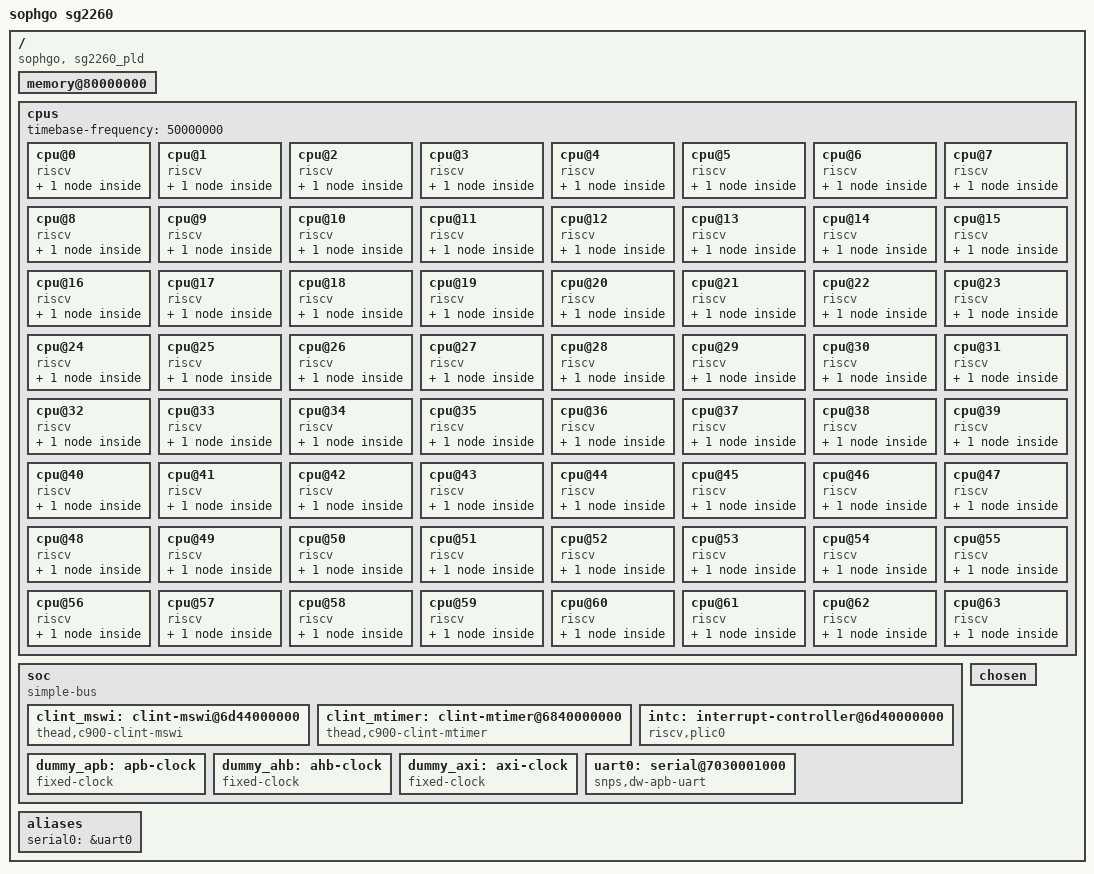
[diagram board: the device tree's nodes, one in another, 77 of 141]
/dts-v1/;
/ {
	model = "sophgo sg2260";
	compatible = "sophgo, sg2260_pld";
	#address-cells = <2>;
	#size-cells = <2>;
	dma-noncoherent;

	memory@80000000 {
		device_type = "memory";
		reg = <0x00000000 0x80000000 0x00000000 0x80000000>;
	};

	cpus {
		#address-cells = <1>;
		#size-cells = <0>;
		timebase-frequency = <50000000>;
		cpu@0 {
			device_type = "cpu";
			reg = <0>;
			status = "okay";
			compatible = "riscv";
			riscv,isa = "rv64imafdcv_zicbom_zicbop_zicboz_zicond1p0_zihintntl0p2_zihintpause_zawrs_zfa0p1_zfbfmin0p8_zfh_zca_zcb_zcd_zba_zbb_zbc_zbs_zvfbfmin0p8_zvfbfwma0p8_zvfh0p1_sscofpmf_sstc_svinval_svnapot_svpbmt_xtheadc_xtheadvdot";
			riscv,cbom-block-size = <64>;
			riscv,cboz-block-size = <64>;
			mmu-type = "riscv,sv48";
			cpu0_intc: interrupt-controller {
				#interrupt-cells = <1>;
				compatible = "riscv,cpu-intc";
				interrupt-controller;
			};
		};
		cpu@1 {
			device_type = "cpu";
			reg = <1>;
			status = "okay";
			compatible = "riscv";
			riscv,isa = "rv64imafdcv_zicbom_zicbop_zicboz_zicond1p0_zihintntl0p2_zihintpause_zawrs_zfa0p1_zfbfmin0p8_zfh_zca_zcb_zcd_zba_zbb_zbc_zbs_zvfbfmin0p8_zvfbfwma0p8_zvfh0p1_sscofpmf_sstc_svinval_svnapot_svpbmt_xtheadc_xtheadvdot";
			riscv,cbom-block-size = <64>;
			riscv,cboz-block-size = <64>;
			mmu-type = "riscv,sv48";
			cpu1_intc: interrupt-controller {
				#interrupt-cells = <1>;
				compatible = "riscv,cpu-intc";
				interrupt-controller;
			};
		};
		cpu@2 {
			device_type = "cpu";
			reg = <2>;
			status = "okay";
			compatible = "riscv";
			riscv,isa = "rv64imafdcv_zicbom_zicbop_zicboz_zicond1p0_zihintntl0p2_zihintpause_zawrs_zfa0p1_zfbfmin0p8_zfh_zca_zcb_zcd_zba_zbb_zbc_zbs_zvfbfmin0p8_zvfbfwma0p8_zvfh0p1_sscofpmf_sstc_svinval_svnapot_svpbmt_xtheadc_xtheadvdot";
			riscv,cbom-block-size = <64>;
			riscv,cboz-block-size = <64>;
			mmu-type = "riscv,sv48";
			cpu2_intc: interrupt-controller {
				#interrupt-cells = <1>;
				compatible = "riscv,cpu-intc";
				interrupt-controller;
			};
		};
		cpu@3 {
			device_type = "cpu";
			reg = <3>;
			status = "okay";
			compatible = "riscv";
			riscv,isa = "rv64imafdcv_zicbom_zicbop_zicboz_zicond1p0_zihintntl0p2_zihintpause_zawrs_zfa0p1_zfbfmin0p8_zfh_zca_zcb_zcd_zba_zbb_zbc_zbs_zvfbfmin0p8_zvfbfwma0p8_zvfh0p1_sscofpmf_sstc_svinval_svnapot_svpbmt_xtheadc_xtheadvdot";
			riscv,cbom-block-size = <64>;
			riscv,cboz-block-size = <64>;
			mmu-type = "riscv,sv48";
			cpu3_intc: interrupt-controller {
				#interrupt-cells = <1>;
				compatible = "riscv,cpu-intc";
				interrupt-controller;
			};
		};
		cpu@4 {
			device_type = "cpu";
			reg = <4>;
			status = "okay";
			compatible = "riscv";
			riscv,isa = "rv64imafdcv_zicbom_zicbop_zicboz_zicond1p0_zihintntl0p2_zihintpause_zawrs_zfa0p1_zfbfmin0p8_zfh_zca_zcb_zcd_zba_zbb_zbc_zbs_zvfbfmin0p8_zvfbfwma0p8_zvfh0p1_sscofpmf_sstc_svinval_svnapot_svpbmt_xtheadc_xtheadvdot";
			riscv,cbom-block-size = <64>;
			riscv,cboz-block-size = <64>;
			mmu-type = "riscv,sv48";
			cpu4_intc: interrupt-controller {
				#interrupt-cells = <1>;
				compatible = "riscv,cpu-intc";
				interrupt-controller;
			};
		};
		cpu@5 {
			device_type = "cpu";
			reg = <5>;
			status = "okay";
			compatible = "riscv";
			riscv,isa = "rv64imafdcv_zicbom_zicbop_zicboz_zicond1p0_zihintntl0p2_zihintpause_zawrs_zfa0p1_zfbfmin0p8_zfh_zca_zcb_zcd_zba_zbb_zbc_zbs_zvfbfmin0p8_zvfbfwma0p8_zvfh0p1_sscofpmf_sstc_svinval_svnapot_svpbmt_xtheadc_xtheadvdot";
			riscv,cbom-block-size = <64>;
			riscv,cboz-block-size = <64>;
			mmu-type = "riscv,sv48";
			cpu5_intc: interrupt-controller {
				#interrupt-cells = <1>;
				compatible = "riscv,cpu-intc";
				interrupt-controller;
			};
		};
		cpu@6 {
			device_type = "cpu";
			reg = <6>;
			status = "okay";
			compatible = "riscv";
			riscv,isa = "rv64imafdcv_zicbom_zicbop_zicboz_zicond1p0_zihintntl0p2_zihintpause_zawrs_zfa0p1_zfbfmin0p8_zfh_zca_zcb_zcd_zba_zbb_zbc_zbs_zvfbfmin0p8_zvfbfwma0p8_zvfh0p1_sscofpmf_sstc_svinval_svnapot_svpbmt_xtheadc_xtheadvdot";
			riscv,cbom-block-size = <64>;
			riscv,cboz-block-size = <64>;
			mmu-type = "riscv,sv48";
			cpu6_intc: interrupt-controller {
				#interrupt-cells = <1>;
				compatible = "riscv,cpu-intc";
				interrupt-controller;
			};
		};
		cpu@7 {
			device_type = "cpu";
			reg = <7>;
			status = "okay";
			compatible = "riscv";
			riscv,isa = "rv64imafdcv_zicbom_zicbop_zicboz_zicond1p0_zihintntl0p2_zihintpause_zawrs_zfa0p1_zfbfmin0p8_zfh_zca_zcb_zcd_zba_zbb_zbc_zbs_zvfbfmin0p8_zvfbfwma0p8_zvfh0p1_sscofpmf_sstc_svinval_svnapot_svpbmt_xtheadc_xtheadvdot";
			riscv,cbom-block-size = <64>;
			riscv,cboz-block-size = <64>;
			mmu-type = "riscv,sv48";
			cpu7_intc: interrupt-controller {
				#interrupt-cells = <1>;
				compatible = "riscv,cpu-intc";
				interrupt-controller;
			};
		};
		cpu@8 {
			device_type = "cpu";
			reg = <8>;
			status = "okay";
			compatible = "riscv";
			riscv,isa = "rv64imafdcv_zicbom_zicbop_zicboz_zicond1p0_zihintntl0p2_zihintpause_zawrs_zfa0p1_zfbfmin0p8_zfh_zca_zcb_zcd_zba_zbb_zbc_zbs_zvfbfmin0p8_zvfbfwma0p8_zvfh0p1_sscofpmf_sstc_svinval_svnapot_svpbmt_xtheadc_xtheadvdot";
			riscv,cbom-block-size = <64>;
			riscv,cboz-block-size = <64>;
			mmu-type = "riscv,sv48";
			cpu8_intc: interrupt-controller {
				#interrupt-cells = <1>;
				compatible = "riscv,cpu-intc";
				interrupt-controller;
			};
		};
		cpu@9 {
			device_type = "cpu";
			reg = <9>;
			status = "okay";
			compatible = "riscv";
			riscv,isa = "rv64imafdcv_zicbom_zicbop_zicboz_zicond1p0_zihintntl0p2_zihintpause_zawrs_zfa0p1_zfbfmin0p8_zfh_zca_zcb_zcd_zba_zbb_zbc_zbs_zvfbfmin0p8_zvfbfwma0p8_zvfh0p1_sscofpmf_sstc_svinval_svnapot_svpbmt_xtheadc_xtheadvdot";
			riscv,cbom-block-size = <64>;
			riscv,cboz-block-size = <64>;
			mmu-type = "riscv,sv48";
			cpu9_intc: interrupt-controller {
				#interrupt-cells = <1>;
				compatible = "riscv,cpu-intc";
				interrupt-controller;
			};
		};
		cpu@10 {
			device_type = "cpu";
			reg = <10>;
			status = "okay";
			compatible = "riscv";
			riscv,isa = "rv64imafdcv_zicbom_zicbop_zicboz_zicond1p0_zihintntl0p2_zihintpause_zawrs_zfa0p1_zfbfmin0p8_zfh_zca_zcb_zcd_zba_zbb_zbc_zbs_zvfbfmin0p8_zvfbfwma0p8_zvfh0p1_sscofpmf_sstc_svinval_svnapot_svpbmt_xtheadc_xtheadvdot";
			riscv,cbom-block-size = <64>;
			riscv,cboz-block-size = <64>;
			mmu-type = "riscv,sv48";
			cpu10_intc: interrupt-controller {
				#interrupt-cells = <1>;
				compatible = "riscv,cpu-intc";
				interrupt-controller;
			};
		};
		cpu@11 {
			device_type = "cpu";
			reg = <11>;
			status = "okay";
			compatible = "riscv";
			riscv,isa = "rv64imafdcv_zicbom_zicbop_zicboz_zicond1p0_zihintntl0p2_zihintpause_zawrs_zfa0p1_zfbfmin0p8_zfh_zca_zcb_zcd_zba_zbb_zbc_zbs_zvfbfmin0p8_zvfbfwma0p8_zvfh0p1_sscofpmf_sstc_svinval_svnapot_svpbmt_xtheadc_xtheadvdot";
			riscv,cbom-block-size = <64>;
			riscv,cboz-block-size = <64>;
			mmu-type = "riscv,sv48";
			cpu11_intc: interrupt-controller {
				#interrupt-cells = <1>;
				compatible = "riscv,cpu-intc";
				interrupt-controller;
			};
		};
		cpu@12 {
			device_type = "cpu";
			reg = <12>;
			status = "okay";
			compatible = "riscv";
			riscv,isa = "rv64imafdcv_zicbom_zicbop_zicboz_zicond1p0_zihintntl0p2_zihintpause_zawrs_zfa0p1_zfbfmin0p8_zfh_zca_zcb_zcd_zba_zbb_zbc_zbs_zvfbfmin0p8_zvfbfwma0p8_zvfh0p1_sscofpmf_sstc_svinval_svnapot_svpbmt_xtheadc_xtheadvdot";
			riscv,cbom-block-size = <64>;
			riscv,cboz-block-size = <64>;
			mmu-type = "riscv,sv48";
			cpu12_intc: interrupt-controller {
				#interrupt-cells = <1>;
				compatible = "riscv,cpu-intc";
				interrupt-controller;
			};
		};
		cpu@13 {
			device_type = "cpu";
			reg = <13>;
			status = "okay";
			compatible = "riscv";
			riscv,isa = "rv64imafdcv_zicbom_zicbop_zicboz_zicond1p0_zihintntl0p2_zihintpause_zawrs_zfa0p1_zfbfmin0p8_zfh_zca_zcb_zcd_zba_zbb_zbc_zbs_zvfbfmin0p8_zvfbfwma0p8_zvfh0p1_sscofpmf_sstc_svinval_svnapot_svpbmt_xtheadc_xtheadvdot";
			riscv,cbom-block-size = <64>;
			riscv,cboz-block-size = <64>;
			mmu-type = "riscv,sv48";
			cpu13_intc: interrupt-controller {
				#interrupt-cells = <1>;
				compatible = "riscv,cpu-intc";
				interrupt-controller;
			};
		};
		cpu@14 {
			device_type = "cpu";
			reg = <14>;
			status = "okay";
			compatible = "riscv";
			riscv,isa = "rv64imafdcv_zicbom_zicbop_zicboz_zicond1p0_zihintntl0p2_zihintpause_zawrs_zfa0p1_zfbfmin0p8_zfh_zca_zcb_zcd_zba_zbb_zbc_zbs_zvfbfmin0p8_zvfbfwma0p8_zvfh0p1_sscofpmf_sstc_svinval_svnapot_svpbmt_xtheadc_xtheadvdot";
			riscv,cbom-block-size = <64>;
			riscv,cboz-block-size = <64>;
			mmu-type = "riscv,sv48";
			cpu14_intc: interrupt-controller {
				#interrupt-cells = <1>;
				compatible = "riscv,cpu-intc";
				interrupt-controller;
			};
		};
		cpu@15 {
			device_type = "cpu";
			reg = <15>;
			status = "okay";
			compatible = "riscv";
			riscv,isa = "rv64imafdcv_zicbom_zicbop_zicboz_zicond1p0_zihintntl0p2_zihintpause_zawrs_zfa0p1_zfbfmin0p8_zfh_zca_zcb_zcd_zba_zbb_zbc_zbs_zvfbfmin0p8_zvfbfwma0p8_zvfh0p1_sscofpmf_sstc_svinval_svnapot_svpbmt_xtheadc_xtheadvdot";
			riscv,cbom-block-size = <64>;
			riscv,cboz-block-size = <64>;
			mmu-type = "riscv,sv48";
			cpu15_intc: interrupt-controller {
				#interrupt-cells = <1>;
				compatible = "riscv,cpu-intc";
				interrupt-controller;
			};
		};
		cpu@16 {
			device_type = "cpu";
			reg = <16>;
			status = "okay";
			compatible = "riscv";
			riscv,isa = "rv64imafdcv_zicbom_zicbop_zicboz_zicond1p0_zihintntl0p2_zihintpause_zawrs_zfa0p1_zfbfmin0p8_zfh_zca_zcb_zcd_zba_zbb_zbc_zbs_zvfbfmin0p8_zvfbfwma0p8_zvfh0p1_sscofpmf_sstc_svinval_svnapot_svpbmt_xtheadc_xtheadvdot";
			riscv,cbom-block-size = <64>;
			riscv,cboz-block-size = <64>;
			mmu-type = "riscv,sv48";
			cpu16_intc: interrupt-controller {
				#interrupt-cells = <1>;
				compatible = "riscv,cpu-intc";
				interrupt-controller;
			};
		};
		cpu@17 {
			device_type = "cpu";
			reg = <17>;
			status = "okay";
			compatible = "riscv";
			riscv,isa = "rv64imafdcv_zicbom_zicbop_zicboz_zicond1p0_zihintntl0p2_zihintpause_zawrs_zfa0p1_zfbfmin0p8_zfh_zca_zcb_zcd_zba_zbb_zbc_zbs_zvfbfmin0p8_zvfbfwma0p8_zvfh0p1_sscofpmf_sstc_svinval_svnapot_svpbmt_xtheadc_xtheadvdot";
			riscv,cbom-block-size = <64>;
			riscv,cboz-block-size = <64>;
			mmu-type = "riscv,sv48";
			cpu17_intc: interrupt-controller {
				#interrupt-cells = <1>;
				compatible = "riscv,cpu-intc";
				interrupt-controller;
			};
		};
		cpu@18 {
			device_type = "cpu";
			reg = <18>;
			status = "okay";
			compatible = "riscv";
			riscv,isa = "rv64imafdcv_zicbom_zicbop_zicboz_zicond1p0_zihintntl0p2_zihintpause_zawrs_zfa0p1_zfbfmin0p8_zfh_zca_zcb_zcd_zba_zbb_zbc_zbs_zvfbfmin0p8_zvfbfwma0p8_zvfh0p1_sscofpmf_sstc_svinval_svnapot_svpbmt_xtheadc_xtheadvdot";
			riscv,cbom-block-size = <64>;
			riscv,cboz-block-size = <64>;
			mmu-type = "riscv,sv48";
			cpu18_intc: interrupt-controller {
				#interrupt-cells = <1>;
				compatible = "riscv,cpu-intc";
				interrupt-controller;
			};
		};
		cpu@19 {
			device_type = "cpu";
			reg = <19>;
			status = "okay";
			compatible = "riscv";
			riscv,isa = "rv64imafdcv_zicbom_zicbop_zicboz_zicond1p0_zihintntl0p2_zihintpause_zawrs_zfa0p1_zfbfmin0p8_zfh_zca_zcb_zcd_zba_zbb_zbc_zbs_zvfbfmin0p8_zvfbfwma0p8_zvfh0p1_sscofpmf_sstc_svinval_svnapot_svpbmt_xtheadc_xtheadvdot";
			riscv,cbom-block-size = <64>;
			riscv,cboz-block-size = <64>;
			mmu-type = "riscv,sv48";
			cpu19_intc: interrupt-controller {
				#interrupt-cells = <1>;
				compatible = "riscv,cpu-intc";
				interrupt-controller;
			};
		};
		cpu@20 {
			device_type = "cpu";
			reg = <20>;
			status = "okay";
			compatible = "riscv";
			riscv,isa = "rv64imafdcv_zicbom_zicbop_zicboz_zicond1p0_zihintntl0p2_zihintpause_zawrs_zfa0p1_zfbfmin0p8_zfh_zca_zcb_zcd_zba_zbb_zbc_zbs_zvfbfmin0p8_zvfbfwma0p8_zvfh0p1_sscofpmf_sstc_svinval_svnapot_svpbmt_xtheadc_xtheadvdot";
			riscv,cbom-block-size = <64>;
			riscv,cboz-block-size = <64>;
			mmu-type = "riscv,sv48";
			cpu20_intc: interrupt-controller {
				#interrupt-cells = <1>;
				compatible = "riscv,cpu-intc";
				interrupt-controller;
			};
		};
		cpu@21 {
			device_type = "cpu";
			reg = <21>;
			status = "okay";
			compatible = "riscv";
			riscv,isa = "rv64imafdcv_zicbom_zicbop_zicboz_zicond1p0_zihintntl0p2_zihintpause_zawrs_zfa0p1_zfbfmin0p8_zfh_zca_zcb_zcd_zba_zbb_zbc_zbs_zvfbfmin0p8_zvfbfwma0p8_zvfh0p1_sscofpmf_sstc_svinval_svnapot_svpbmt_xtheadc_xtheadvdot";
			riscv,cbom-block-size = <64>;
			riscv,cboz-block-size = <64>;
			mmu-type = "riscv,sv48";
			cpu21_intc: interrupt-controller {
				#interrupt-cells = <1>;
				compatible = "riscv,cpu-intc";
				interrupt-controller;
			};
		};
		cpu@22 {
			device_type = "cpu";
			reg = <22>;
			status = "okay";
			compatible = "riscv";
			riscv,isa = "rv64imafdcv_zicbom_zicbop_zicboz_zicond1p0_zihintntl0p2_zihintpause_zawrs_zfa0p1_zfbfmin0p8_zfh_zca_zcb_zcd_zba_zbb_zbc_zbs_zvfbfmin0p8_zvfbfwma0p8_zvfh0p1_sscofpmf_sstc_svinval_svnapot_svpbmt_xtheadc_xtheadvdot";
			riscv,cbom-block-size = <64>;
			riscv,cboz-block-size = <64>;
			mmu-type = "riscv,sv48";
			cpu22_intc: interrupt-controller {
				#interrupt-cells = <1>;
				compatible = "riscv,cpu-intc";
				interrupt-controller;
			};
		};
		cpu@23 {
			device_type = "cpu";
			reg = <23>;
			status = "okay";
			compatible = "riscv";
			riscv,isa = "rv64imafdcv_zicbom_zicbop_zicboz_zicond1p0_zihintntl0p2_zihintpause_zawrs_zfa0p1_zfbfmin0p8_zfh_zca_zcb_zcd_zba_zbb_zbc_zbs_zvfbfmin0p8_zvfbfwma0p8_zvfh0p1_sscofpmf_sstc_svinval_svnapot_svpbmt_xtheadc_xtheadvdot";
			riscv,cbom-block-size = <64>;
			riscv,cboz-block-size = <64>;
			mmu-type = "riscv,sv48";
			cpu23_intc: interrupt-controller {
				#interrupt-cells = <1>;
				compatible = "riscv,cpu-intc";
				interrupt-controller;
			};
		};
		cpu@24 {
			device_type = "cpu";
			reg = <24>;
			status = "okay";
			compatible = "riscv";
			riscv,isa = "rv64imafdcv_zicbom_zicbop_zicboz_zicond1p0_zihintntl0p2_zihintpause_zawrs_zfa0p1_zfbfmin0p8_zfh_zca_zcb_zcd_zba_zbb_zbc_zbs_zvfbfmin0p8_zvfbfwma0p8_zvfh0p1_sscofpmf_sstc_svinval_svnapot_svpbmt_xtheadc_xtheadvdot";
			riscv,cbom-block-size = <64>;
			riscv,cboz-block-size = <64>;
			mmu-type = "riscv,sv48";
			cpu24_intc: interrupt-controller {
				#interrupt-cells = <1>;
				compatible = "riscv,cpu-intc";
				interrupt-controller;
			};
		};
		cpu@25 {
			device_type = "cpu";
			reg = <25>;
			status = "okay";
			compatible = "riscv";
			riscv,isa = "rv64imafdcv_zicbom_zicbop_zicboz_zicond1p0_zihintntl0p2_zihintpause_zawrs_zfa0p1_zfbfmin0p8_zfh_zca_zcb_zcd_zba_zbb_zbc_zbs_zvfbfmin0p8_zvfbfwma0p8_zvfh0p1_sscofpmf_sstc_svinval_svnapot_svpbmt_xtheadc_xtheadvdot";
			riscv,cbom-block-size = <64>;
			riscv,cboz-block-size = <64>;
			mmu-type = "riscv,sv48";
			cpu25_intc: interrupt-controller {
				#interrupt-cells = <1>;
				compatible = "riscv,cpu-intc";
				interrupt-controller;
			};
		};
		cpu@26 {
			device_type = "cpu";
			reg = <26>;
			status = "okay";
			compatible = "riscv";
			riscv,isa = "rv64imafdcv_zicbom_zicbop_zicboz_zicond1p0_zihintntl0p2_zihintpause_zawrs_zfa0p1_zfbfmin0p8_zfh_zca_zcb_zcd_zba_zbb_zbc_zbs_zvfbfmin0p8_zvfbfwma0p8_zvfh0p1_sscofpmf_sstc_svinval_svnapot_svpbmt_xtheadc_xtheadvdot";
			riscv,cbom-block-size = <64>;
			riscv,cboz-block-size = <64>;
			mmu-type = "riscv,sv48";
			cpu26_intc: interrupt-controller {
				#interrupt-cells = <1>;
				compatible = "riscv,cpu-intc";
				interrupt-controller;
			};
		};
		cpu@27 {
			device_type = "cpu";
			reg = <27>;
			status = "okay";
			compatible = "riscv";
			riscv,isa = "rv64imafdcv_zicbom_zicbop_zicboz_zicond1p0_zihintntl0p2_zihintpause_zawrs_zfa0p1_zfbfmin0p8_zfh_zca_zcb_zcd_zba_zbb_zbc_zbs_zvfbfmin0p8_zvfbfwma0p8_zvfh0p1_sscofpmf_sstc_svinval_svnapot_svpbmt_xtheadc_xtheadvdot";
			riscv,cbom-block-size = <64>;
			riscv,cboz-block-size = <64>;
			mmu-type = "riscv,sv48";
			cpu27_intc: interrupt-controller {
				#interrupt-cells = <1>;
				compatible = "riscv,cpu-intc";
				interrupt-controller;
			};
		};
		cpu@28 {
			device_type = "cpu";
			reg = <28>;
			status = "okay";
			compatible = "riscv";
			riscv,isa = "rv64imafdcv_zicbom_zicbop_zicboz_zicond1p0_zihintntl0p2_zihintpause_zawrs_zfa0p1_zfbfmin0p8_zfh_zca_zcb_zcd_zba_zbb_zbc_zbs_zvfbfmin0p8_zvfbfwma0p8_zvfh0p1_sscofpmf_sstc_svinval_svnapot_svpbmt_xtheadc_xtheadvdot";
			riscv,cbom-block-size = <64>;
			riscv,cboz-block-size = <64>;
			mmu-type = "riscv,sv48";
			cpu28_intc: interrupt-controller {
				#interrupt-cells = <1>;
				compatible = "riscv,cpu-intc";
				interrupt-controller;
			};
		};
		cpu@29 {
			device_type = "cpu";
			reg = <29>;
			status = "okay";
			compatible = "riscv";
			riscv,isa = "rv64imafdcv_zicbom_zicbop_zicboz_zicond1p0_zihintntl0p2_zihintpause_zawrs_zfa0p1_zfbfmin0p8_zfh_zca_zcb_zcd_zba_zbb_zbc_zbs_zvfbfmin0p8_zvfbfwma0p8_zvfh0p1_sscofpmf_sstc_svinval_svnapot_svpbmt_xtheadc_xtheadvdot";
			riscv,cbom-block-size = <64>;
			riscv,cboz-block-size = <64>;
			mmu-type = "riscv,sv48";
			cpu29_intc: interrupt-controller {
				#interrupt-cells = <1>;
				compatible = "riscv,cpu-intc";
				interrupt-controller;
			};
		};
		cpu@30 {
			device_type = "cpu";
			reg = <30>;
			status = "okay";
			compatible = "riscv";
			riscv,isa = "rv64imafdcv_zicbom_zicbop_zicboz_zicond1p0_zihintntl0p2_zihintpause_zawrs_zfa0p1_zfbfmin0p8_zfh_zca_zcb_zcd_zba_zbb_zbc_zbs_zvfbfmin0p8_zvfbfwma0p8_zvfh0p1_sscofpmf_sstc_svinval_svnapot_svpbmt_xtheadc_xtheadvdot";
			riscv,cbom-block-size = <64>;
			riscv,cboz-block-size = <64>;
			mmu-type = "riscv,sv48";
			cpu30_intc: interrupt-controller {
				#interrupt-cells = <1>;
				compatible = "riscv,cpu-intc";
				interrupt-controller;
			};
		};
		cpu@31 {
			device_type = "cpu";
			reg = <31>;
			status = "okay";
			compatible = "riscv";
			riscv,isa = "rv64imafdcv_zicbom_zicbop_zicboz_zicond1p0_zihintntl0p2_zihintpause_zawrs_zfa0p1_zfbfmin0p8_zfh_zca_zcb_zcd_zba_zbb_zbc_zbs_zvfbfmin0p8_zvfbfwma0p8_zvfh0p1_sscofpmf_sstc_svinval_svnapot_svpbmt_xtheadc_xtheadvdot";
			riscv,cbom-block-size = <64>;
			riscv,cboz-block-size = <64>;
			mmu-type = "riscv,sv48";
			cpu31_intc: interrupt-controller {
				#interrupt-cells = <1>;
				compatible = "riscv,cpu-intc";
				interrupt-controller;
			};
		};
		cpu@32 {
			device_type = "cpu";
			reg = <32>;
			status = "okay";
			compatible = "riscv";
			riscv,isa = "rv64imafdcv_zicbom_zicbop_zicboz_zicond1p0_zihintntl0p2_zihintpause_zawrs_zfa0p1_zfbfmin0p8_zfh_zca_zcb_zcd_zba_zbb_zbc_zbs_zvfbfmin0p8_zvfbfwma0p8_zvfh0p1_sscofpmf_sstc_svinval_svnapot_svpbmt_xtheadc_xtheadvdot";
			riscv,cbom-block-size = <64>;
			riscv,cboz-block-size = <64>;
			mmu-type = "riscv,sv48";
			cpu32_intc: interrupt-controller {
				#interrupt-cells = <1>;
				compatible = "riscv,cpu-intc";
				interrupt-controller;
			};
		};
		cpu@33 {
			device_type = "cpu";
			reg = <33>;
			status = "okay";
			compatible = "riscv";
			riscv,isa = "rv64imafdcv_zicbom_zicbop_zicboz_zicond1p0_zihintntl0p2_zihintpause_zawrs_zfa0p1_zfbfmin0p8_zfh_zca_zcb_zcd_zba_zbb_zbc_zbs_zvfbfmin0p8_zvfbfwma0p8_zvfh0p1_sscofpmf_sstc_svinval_svnapot_svpbmt_xtheadc_xtheadvdot";
			riscv,cbom-block-size = <64>;
			riscv,cboz-block-size = <64>;
			mmu-type = "riscv,sv48";
			cpu33_intc: interrupt-controller {
				#interrupt-cells = <1>;
				compatible = "riscv,cpu-intc";
				interrupt-controller;
			};
		};
		cpu@34 {
			device_type = "cpu";
			reg = <34>;
			status = "okay";
			compatible = "riscv";
			riscv,isa = "rv64imafdcv_zicbom_zicbop_zicboz_zicond1p0_zihintntl0p2_zihintpause_zawrs_zfa0p1_zfbfmin0p8_zfh_zca_zcb_zcd_zba_zbb_zbc_zbs_zvfbfmin0p8_zvfbfwma0p8_zvfh0p1_sscofpmf_sstc_svinval_svnapot_svpbmt_xtheadc_xtheadvdot";
			riscv,cbom-block-size = <64>;
			riscv,cboz-block-size = <64>;
			mmu-type = "riscv,sv48";
			cpu34_intc: interrupt-controller {
				#interrupt-cells = <1>;
				compatible = "riscv,cpu-intc";
				interrupt-controller;
			};
		};
		cpu@35 {
			device_type = "cpu";
			reg = <35>;
			status = "okay";
			compatible = "riscv";
			riscv,isa = "rv64imafdcv_zicbom_zicbop_zicboz_zicond1p0_zihintntl0p2_zihintpause_zawrs_zfa0p1_zfbfmin0p8_zfh_zca_zcb_zcd_zba_zbb_zbc_zbs_zvfbfmin0p8_zvfbfwma0p8_zvfh0p1_sscofpmf_sstc_svinval_svnapot_svpbmt_xtheadc_xtheadvdot";
			riscv,cbom-block-size = <64>;
			riscv,cboz-block-size = <64>;
			mmu-type = "riscv,sv48";
			cpu35_intc: interrupt-controller {
				#interrupt-cells = <1>;
				compatible = "riscv,cpu-intc";
				interrupt-controller;
			};
		};
		cpu@36 {
			device_type = "cpu";
			reg = <36>;
			status = "okay";
			compatible = "riscv";
			riscv,isa = "rv64imafdcv_zicbom_zicbop_zicboz_zicond1p0_zihintntl0p2_zihintpause_zawrs_zfa0p1_zfbfmin0p8_zfh_zca_zcb_zcd_zba_zbb_zbc_zbs_zvfbfmin0p8_zvfbfwma0p8_zvfh0p1_sscofpmf_sstc_svinval_svnapot_svpbmt_xtheadc_xtheadvdot";
			riscv,cbom-block-size = <64>;
			riscv,cboz-block-size = <64>;
			mmu-type = "riscv,sv48";
			cpu36_intc: interrupt-controller {
				#interrupt-cells = <1>;
				compatible = "riscv,cpu-intc";
				interrupt-controller;
			};
		};
		cpu@37 {
			device_type = "cpu";
			reg = <37>;
			status = "okay";
			compatible = "riscv";
			riscv,isa = "rv64imafdcv_zicbom_zicbop_zicboz_zicond1p0_zihintntl0p2_zihintpause_zawrs_zfa0p1_zfbfmin0p8_zfh_zca_zcb_zcd_zba_zbb_zbc_zbs_zvfbfmin0p8_zvfbfwma0p8_zvfh0p1_sscofpmf_sstc_svinval_svnapot_svpbmt_xtheadc_xtheadvdot";
			riscv,cbom-block-size = <64>;
			riscv,cboz-block-size = <64>;
			mmu-type = "riscv,sv48";
			cpu37_intc: interrupt-controller {
				#interrupt-cells = <1>;
				compatible = "riscv,cpu-intc";
				interrupt-controller;
			};
		};
		cpu@38 {
			device_type = "cpu";
			reg = <38>;
			status = "okay";
			compatible = "riscv";
			riscv,isa = "rv64imafdcv_zicbom_zicbop_zicboz_zicond1p0_zihintntl0p2_zihintpause_zawrs_zfa0p1_zfbfmin0p8_zfh_zca_zcb_zcd_zba_zbb_zbc_zbs_zvfbfmin0p8_zvfbfwma0p8_zvfh0p1_sscofpmf_sstc_svinval_svnapot_svpbmt_xtheadc_xtheadvdot";
			riscv,cbom-block-size = <64>;
			riscv,cboz-block-size = <64>;
			mmu-type = "riscv,sv48";
			cpu38_intc: interrupt-controller {
				#interrupt-cells = <1>;
				compatible = "riscv,cpu-intc";
				interrupt-controller;
			};
		};
		cpu@39 {
			device_type = "cpu";
			reg = <39>;
			status = "okay";
			compatible = "riscv";
			riscv,isa = "rv64imafdcv_zicbom_zicbop_zicboz_zicond1p0_zihintntl0p2_zihintpause_zawrs_zfa0p1_zfbfmin0p8_zfh_zca_zcb_zcd_zba_zbb_zbc_zbs_zvfbfmin0p8_zvfbfwma0p8_zvfh0p1_sscofpmf_sstc_svinval_svnapot_svpbmt_xtheadc_xtheadvdot";
			riscv,cbom-block-size = <64>;
			riscv,cboz-block-size = <64>;
			mmu-type = "riscv,sv48";
			cpu39_intc: interrupt-controller {
				#interrupt-cells = <1>;
				compatible = "riscv,cpu-intc";
				interrupt-controller;
			};
		};
		cpu@40 {
			device_type = "cpu";
			reg = <40>;
			status = "okay";
			compatible = "riscv";
			riscv,isa = "rv64imafdcv_zicbom_zicbop_zicboz_zicond1p0_zihintntl0p2_zihintpause_zawrs_zfa0p1_zfbfmin0p8_zfh_zca_zcb_zcd_zba_zbb_zbc_zbs_zvfbfmin0p8_zvfbfwma0p8_zvfh0p1_sscofpmf_sstc_svinval_svnapot_svpbmt_xtheadc_xtheadvdot";
			riscv,cbom-block-size = <64>;
			riscv,cboz-block-size = <64>;
			mmu-type = "riscv,sv48";
			cpu40_intc: interrupt-controller {
				#interrupt-cells = <1>;
				compatible = "riscv,cpu-intc";
				interrupt-controller;
			};
		};
		cpu@41 {
			device_type = "cpu";
			reg = <41>;
			status = "okay";
			compatible = "riscv";
			riscv,isa = "rv64imafdcv_zicbom_zicbop_zicboz_zicond1p0_zihintntl0p2_zihintpause_zawrs_zfa0p1_zfbfmin0p8_zfh_zca_zcb_zcd_zba_zbb_zbc_zbs_zvfbfmin0p8_zvfbfwma0p8_zvfh0p1_sscofpmf_sstc_svinval_svnapot_svpbmt_xtheadc_xtheadvdot";
			riscv,cbom-block-size = <64>;
			riscv,cboz-block-size = <64>;
			mmu-type = "riscv,sv48";
			cpu41_intc: interrupt-controller {
				#interrupt-cells = <1>;
				compatible = "riscv,cpu-intc";
				interrupt-controller;
			};
		};
		cpu@42 {
			device_type = "cpu";
			reg = <42>;
			status = "okay";
			compatible = "riscv";
			riscv,isa = "rv64imafdcv_zicbom_zicbop_zicboz_zicond1p0_zihintntl0p2_zihintpause_zawrs_zfa0p1_zfbfmin0p8_zfh_zca_zcb_zcd_zba_zbb_zbc_zbs_zvfbfmin0p8_zvfbfwma0p8_zvfh0p1_sscofpmf_sstc_svinval_svnapot_svpbmt_xtheadc_xtheadvdot";
			riscv,cbom-block-size = <64>;
			riscv,cboz-block-size = <64>;
			mmu-type = "riscv,sv48";
			cpu42_intc: interrupt-controller {
				#interrupt-cells = <1>;
				compatible = "riscv,cpu-intc";
				interrupt-controller;
			};
		};
		cpu@43 {
			device_type = "cpu";
			reg = <43>;
			status = "okay";
			compatible = "riscv";
			riscv,isa = "rv64imafdcv_zicbom_zicbop_zicboz_zicond1p0_zihintntl0p2_zihintpause_zawrs_zfa0p1_zfbfmin0p8_zfh_zca_zcb_zcd_zba_zbb_zbc_zbs_zvfbfmin0p8_zvfbfwma0p8_zvfh0p1_sscofpmf_sstc_svinval_svnapot_svpbmt_xtheadc_xtheadvdot";
			riscv,cbom-block-size = <64>;
			riscv,cboz-block-size = <64>;
			mmu-type = "riscv,sv48";
			cpu43_intc: interrupt-controller {
				#interrupt-cells = <1>;
				compatible = "riscv,cpu-intc";
				interrupt-controller;
			};
		};
		cpu@44 {
			device_type = "cpu";
			reg = <44>;
			status = "okay";
			compatible = "riscv";
			riscv,isa = "rv64imafdcv_zicbom_zicbop_zicboz_zicond1p0_zihintntl0p2_zihintpause_zawrs_zfa0p1_zfbfmin0p8_zfh_zca_zcb_zcd_zba_zbb_zbc_zbs_zvfbfmin0p8_zvfbfwma0p8_zvfh0p1_sscofpmf_sstc_svinval_svnapot_svpbmt_xtheadc_xtheadvdot";
			riscv,cbom-block-size = <64>;
			riscv,cboz-block-size = <64>;
			mmu-type = "riscv,sv48";
			cpu44_intc: interrupt-controller {
				#interrupt-cells = <1>;
				compatible = "riscv,cpu-intc";
				interrupt-controller;
			};
		};
		cpu@45 {
			device_type = "cpu";
			reg = <45>;
			status = "okay";
			compatible = "riscv";
			riscv,isa = "rv64imafdcv_zicbom_zicbop_zicboz_zicond1p0_zihintntl0p2_zihintpause_zawrs_zfa0p1_zfbfmin0p8_zfh_zca_zcb_zcd_zba_zbb_zbc_zbs_zvfbfmin0p8_zvfbfwma0p8_zvfh0p1_sscofpmf_sstc_svinval_svnapot_svpbmt_xtheadc_xtheadvdot";
			riscv,cbom-block-size = <64>;
			riscv,cboz-block-size = <64>;
			mmu-type = "riscv,sv48";
			cpu45_intc: interrupt-controller {
				#interrupt-cells = <1>;
				compatible = "riscv,cpu-intc";
				interrupt-controller;
			};
		};
		cpu@46 {
			device_type = "cpu";
			reg = <46>;
			status = "okay";
			compatible = "riscv";
			riscv,isa = "rv64imafdcv_zicbom_zicbop_zicboz_zicond1p0_zihintntl0p2_zihintpause_zawrs_zfa0p1_zfbfmin0p8_zfh_zca_zcb_zcd_zba_zbb_zbc_zbs_zvfbfmin0p8_zvfbfwma0p8_zvfh0p1_sscofpmf_sstc_svinval_svnapot_svpbmt_xtheadc_xtheadvdot";
			riscv,cbom-block-size = <64>;
			riscv,cboz-block-size = <64>;
			mmu-type = "riscv,sv48";
			cpu46_intc: interrupt-controller {
				#interrupt-cells = <1>;
				compatible = "riscv,cpu-intc";
				interrupt-controller;
			};
		};
		cpu@47 {
			device_type = "cpu";
			reg = <47>;
			status = "okay";
			compatible = "riscv";
			riscv,isa = "rv64imafdcv_zicbom_zicbop_zicboz_zicond1p0_zihintntl0p2_zihintpause_zawrs_zfa0p1_zfbfmin0p8_zfh_zca_zcb_zcd_zba_zbb_zbc_zbs_zvfbfmin0p8_zvfbfwma0p8_zvfh0p1_sscofpmf_sstc_svinval_svnapot_svpbmt_xtheadc_xtheadvdot";
			riscv,cbom-block-size = <64>;
			riscv,cboz-block-size = <64>;
			mmu-type = "riscv,sv48";
			cpu47_intc: interrupt-controller {
				#interrupt-cells = <1>;
				compatible = "riscv,cpu-intc";
				interrupt-controller;
			};
		};
		cpu@48 {
			device_type = "cpu";
			reg = <48>;
			status = "okay";
			compatible = "riscv";
			riscv,isa = "rv64imafdcv_zicbom_zicbop_zicboz_zicond1p0_zihintntl0p2_zihintpause_zawrs_zfa0p1_zfbfmin0p8_zfh_zca_zcb_zcd_zba_zbb_zbc_zbs_zvfbfmin0p8_zvfbfwma0p8_zvfh0p1_sscofpmf_sstc_svinval_svnapot_svpbmt_xtheadc_xtheadvdot";
			riscv,cbom-block-size = <64>;
			riscv,cboz-block-size = <64>;
			mmu-type = "riscv,sv48";
			cpu48_intc: interrupt-controller {
				#interrupt-cells = <1>;
				compatible = "riscv,cpu-intc";
				interrupt-controller;
			};
		};
		cpu@49 {
			device_type = "cpu";
			reg = <49>;
			status = "okay";
			compatible = "riscv";
			riscv,isa = "rv64imafdcv_zicbom_zicbop_zicboz_zicond1p0_zihintntl0p2_zihintpause_zawrs_zfa0p1_zfbfmin0p8_zfh_zca_zcb_zcd_zba_zbb_zbc_zbs_zvfbfmin0p8_zvfbfwma0p8_zvfh0p1_sscofpmf_sstc_svinval_svnapot_svpbmt_xtheadc_xtheadvdot";
			riscv,cbom-block-size = <64>;
			riscv,cboz-block-size = <64>;
			mmu-type = "riscv,sv48";
			cpu49_intc: interrupt-controller {
				#interrupt-cells = <1>;
				compatible = "riscv,cpu-intc";
				interrupt-controller;
			};
		};
		cpu@50 {
			device_type = "cpu";
			reg = <50>;
			status = "okay";
			compatible = "riscv";
			riscv,isa = "rv64imafdcv_zicbom_zicbop_zicboz_zicond1p0_zihintntl0p2_zihintpause_zawrs_zfa0p1_zfbfmin0p8_zfh_zca_zcb_zcd_zba_zbb_zbc_zbs_zvfbfmin0p8_zvfbfwma0p8_zvfh0p1_sscofpmf_sstc_svinval_svnapot_svpbmt_xtheadc_xtheadvdot";
			riscv,cbom-block-size = <64>;
			riscv,cboz-block-size = <64>;
			mmu-type = "riscv,sv48";
			cpu50_intc: interrupt-controller {
				#interrupt-cells = <1>;
				compatible = "riscv,cpu-intc";
				interrupt-controller;
			};
		};
		cpu@51 {
			device_type = "cpu";
			reg = <51>;
			status = "okay";
			compatible = "riscv";
			riscv,isa = "rv64imafdcv_zicbom_zicbop_zicboz_zicond1p0_zihintntl0p2_zihintpause_zawrs_zfa0p1_zfbfmin0p8_zfh_zca_zcb_zcd_zba_zbb_zbc_zbs_zvfbfmin0p8_zvfbfwma0p8_zvfh0p1_sscofpmf_sstc_svinval_svnapot_svpbmt_xtheadc_xtheadvdot";
			riscv,cbom-block-size = <64>;
			riscv,cboz-block-size = <64>;
			mmu-type = "riscv,sv48";
			cpu51_intc: interrupt-controller {
				#interrupt-cells = <1>;
				compatible = "riscv,cpu-intc";
				interrupt-controller;
			};
		};
		cpu@52 {
			device_type = "cpu";
			reg = <52>;
			status = "okay";
			compatible = "riscv";
			riscv,isa = "rv64imafdcv_zicbom_zicbop_zicboz_zicond1p0_zihintntl0p2_zihintpause_zawrs_zfa0p1_zfbfmin0p8_zfh_zca_zcb_zcd_zba_zbb_zbc_zbs_zvfbfmin0p8_zvfbfwma0p8_zvfh0p1_sscofpmf_sstc_svinval_svnapot_svpbmt_xtheadc_xtheadvdot";
			riscv,cbom-block-size = <64>;
			riscv,cboz-block-size = <64>;
			mmu-type = "riscv,sv48";
			cpu52_intc: interrupt-controller {
				#interrupt-cells = <1>;
				compatible = "riscv,cpu-intc";
				interrupt-controller;
			};
		};
		cpu@53 {
			device_type = "cpu";
			reg = <53>;
			status = "okay";
			compatible = "riscv";
			riscv,isa = "rv64imafdcv_zicbom_zicbop_zicboz_zicond1p0_zihintntl0p2_zihintpause_zawrs_zfa0p1_zfbfmin0p8_zfh_zca_zcb_zcd_zba_zbb_zbc_zbs_zvfbfmin0p8_zvfbfwma0p8_zvfh0p1_sscofpmf_sstc_svinval_svnapot_svpbmt_xtheadc_xtheadvdot";
			riscv,cbom-block-size = <64>;
			riscv,cboz-block-size = <64>;
			mmu-type = "riscv,sv48";
			cpu53_intc: interrupt-controller {
				#interrupt-cells = <1>;
				compatible = "riscv,cpu-intc";
				interrupt-controller;
			};
		};
		cpu@54 {
			device_type = "cpu";
			reg = <54>;
			status = "okay";
			compatible = "riscv";
			riscv,isa = "rv64imafdcv_zicbom_zicbop_zicboz_zicond1p0_zihintntl0p2_zihintpause_zawrs_zfa0p1_zfbfmin0p8_zfh_zca_zcb_zcd_zba_zbb_zbc_zbs_zvfbfmin0p8_zvfbfwma0p8_zvfh0p1_sscofpmf_sstc_svinval_svnapot_svpbmt_xtheadc_xtheadvdot";
			riscv,cbom-block-size = <64>;
			riscv,cboz-block-size = <64>;
			mmu-type = "riscv,sv48";
			cpu54_intc: interrupt-controller {
				#interrupt-cells = <1>;
				compatible = "riscv,cpu-intc";
				interrupt-controller;
			};
		};
		cpu@55 {
			device_type = "cpu";
			reg = <55>;
			status = "okay";
			compatible = "riscv";
			riscv,isa = "rv64imafdcv_zicbom_zicbop_zicboz_zicond1p0_zihintntl0p2_zihintpause_zawrs_zfa0p1_zfbfmin0p8_zfh_zca_zcb_zcd_zba_zbb_zbc_zbs_zvfbfmin0p8_zvfbfwma0p8_zvfh0p1_sscofpmf_sstc_svinval_svnapot_svpbmt_xtheadc_xtheadvdot";
			riscv,cbom-block-size = <64>;
			riscv,cboz-block-size = <64>;
			mmu-type = "riscv,sv48";
			cpu55_intc: interrupt-controller {
				#interrupt-cells = <1>;
				compatible = "riscv,cpu-intc";
				interrupt-controller;
			};
		};
		cpu@56 {
			device_type = "cpu";
			reg = <56>;
			status = "okay";
			compatible = "riscv";
			riscv,isa = "rv64imafdcv_zicbom_zicbop_zicboz_zicond1p0_zihintntl0p2_zihintpause_zawrs_zfa0p1_zfbfmin0p8_zfh_zca_zcb_zcd_zba_zbb_zbc_zbs_zvfbfmin0p8_zvfbfwma0p8_zvfh0p1_sscofpmf_sstc_svinval_svnapot_svpbmt_xtheadc_xtheadvdot";
			riscv,cbom-block-size = <64>;
			riscv,cboz-block-size = <64>;
			mmu-type = "riscv,sv48";
			cpu56_intc: interrupt-controller {
				#interrupt-cells = <1>;
				compatible = "riscv,cpu-intc";
				interrupt-controller;
			};
		};
		cpu@57 {
			device_type = "cpu";
			reg = <57>;
			status = "okay";
			compatible = "riscv";
			riscv,isa = "rv64imafdcv_zicbom_zicbop_zicboz_zicond1p0_zihintntl0p2_zihintpause_zawrs_zfa0p1_zfbfmin0p8_zfh_zca_zcb_zcd_zba_zbb_zbc_zbs_zvfbfmin0p8_zvfbfwma0p8_zvfh0p1_sscofpmf_sstc_svinval_svnapot_svpbmt_xtheadc_xtheadvdot";
			riscv,cbom-block-size = <64>;
			riscv,cboz-block-size = <64>;
			mmu-type = "riscv,sv48";
			cpu57_intc: interrupt-controller {
				#interrupt-cells = <1>;
				compatible = "riscv,cpu-intc";
				interrupt-controller;
			};
		};
		cpu@58 {
			device_type = "cpu";
			reg = <58>;
			status = "okay";
			compatible = "riscv";
			riscv,isa = "rv64imafdcv_zicbom_zicbop_zicboz_zicond1p0_zihintntl0p2_zihintpause_zawrs_zfa0p1_zfbfmin0p8_zfh_zca_zcb_zcd_zba_zbb_zbc_zbs_zvfbfmin0p8_zvfbfwma0p8_zvfh0p1_sscofpmf_sstc_svinval_svnapot_svpbmt_xtheadc_xtheadvdot";
			riscv,cbom-block-size = <64>;
			riscv,cboz-block-size = <64>;
			mmu-type = "riscv,sv48";
			cpu58_intc: interrupt-controller {
				#interrupt-cells = <1>;
				compatible = "riscv,cpu-intc";
				interrupt-controller;
			};
		};
		cpu@59 {
			device_type = "cpu";
			reg = <59>;
			status = "okay";
			compatible = "riscv";
			riscv,isa = "rv64imafdcv_zicbom_zicbop_zicboz_zicond1p0_zihintntl0p2_zihintpause_zawrs_zfa0p1_zfbfmin0p8_zfh_zca_zcb_zcd_zba_zbb_zbc_zbs_zvfbfmin0p8_zvfbfwma0p8_zvfh0p1_sscofpmf_sstc_svinval_svnapot_svpbmt_xtheadc_xtheadvdot";
			riscv,cbom-block-size = <64>;
			riscv,cboz-block-size = <64>;
			mmu-type = "riscv,sv48";
			cpu59_intc: interrupt-controller {
				#interrupt-cells = <1>;
				compatible = "riscv,cpu-intc";
				interrupt-controller;
			};
		};
		cpu@60 {
			device_type = "cpu";
			reg = <60>;
			status = "okay";
			compatible = "riscv";
			riscv,isa = "rv64imafdcv_zicbom_zicbop_zicboz_zicond1p0_zihintntl0p2_zihintpause_zawrs_zfa0p1_zfbfmin0p8_zfh_zca_zcb_zcd_zba_zbb_zbc_zbs_zvfbfmin0p8_zvfbfwma0p8_zvfh0p1_sscofpmf_sstc_svinval_svnapot_svpbmt_xtheadc_xtheadvdot";
			riscv,cbom-block-size = <64>;
			riscv,cboz-block-size = <64>;
			mmu-type = "riscv,sv48";
			cpu60_intc: interrupt-controller {
				#interrupt-cells = <1>;
				compatible = "riscv,cpu-intc";
				interrupt-controller;
			};
		};
		cpu@61 {
			device_type = "cpu";
			reg = <61>;
			status = "okay";
			compatible = "riscv";
			riscv,isa = "rv64imafdcv_zicbom_zicbop_zicboz_zicond1p0_zihintntl0p2_zihintpause_zawrs_zfa0p1_zfbfmin0p8_zfh_zca_zcb_zcd_zba_zbb_zbc_zbs_zvfbfmin0p8_zvfbfwma0p8_zvfh0p1_sscofpmf_sstc_svinval_svnapot_svpbmt_xtheadc_xtheadvdot";
			riscv,cbom-block-size = <64>;
			riscv,cboz-block-size = <64>;
			mmu-type = "riscv,sv48";
			cpu61_intc: interrupt-controller {
				#interrupt-cells = <1>;
				compatible = "riscv,cpu-intc";
				interrupt-controller;
			};
		};
		cpu@62 {
			device_type = "cpu";
			reg = <62>;
			status = "okay";
			compatible = "riscv";
			riscv,isa = "rv64imafdcv_zicbom_zicbop_zicboz_zicond1p0_zihintntl0p2_zihintpause_zawrs_zfa0p1_zfbfmin0p8_zfh_zca_zcb_zcd_zba_zbb_zbc_zbs_zvfbfmin0p8_zvfbfwma0p8_zvfh0p1_sscofpmf_sstc_svinval_svnapot_svpbmt_xtheadc_xtheadvdot";
			riscv,cbom-block-size = <64>;
			riscv,cboz-block-size = <64>;
			mmu-type = "riscv,sv48";
			cpu62_intc: interrupt-controller {
				#interrupt-cells = <1>;
				compatible = "riscv,cpu-intc";
				interrupt-controller;
			};
		};
		cpu@63 {
			device_type = "cpu";
			reg = <63>;
			status = "okay";
			compatible = "riscv";
			riscv,isa = "rv64imafdcv_zicbom_zicbop_zicboz_zicond1p0_zihintntl0p2_zihintpause_zawrs_zfa0p1_zfbfmin0p8_zfh_zca_zcb_zcd_zba_zbb_zbc_zbs_zvfbfmin0p8_zvfbfwma0p8_zvfh0p1_sscofpmf_sstc_svinval_svnapot_svpbmt_xtheadc_xtheadvdot";
			riscv,cbom-block-size = <64>;
			riscv,cboz-block-size = <64>;
			mmu-type = "riscv,sv48";
			cpu63_intc: interrupt-controller {
				#interrupt-cells = <1>;
				compatible = "riscv,cpu-intc";
				interrupt-controller;
			};
		};
	};

	soc {
		#address-cells = <2>;
		#size-cells = <2>;
		compatible = "simple-bus";
		ranges;

		clint_mswi: clint-mswi@6d44000000 {
			compatible = "thead,c900-clint-mswi";
			reg = <0x0000006d 0x44000000 0x00000000 0x00004000>;
			interrupts-extended = <
				&cpu0_intc 3
				&cpu1_intc 3
				&cpu2_intc 3
				&cpu3_intc 3
				&cpu4_intc 3
				&cpu5_intc 3
				&cpu6_intc 3
				&cpu7_intc 3
				&cpu8_intc 3
				&cpu9_intc 3
				&cpu10_intc 3
				&cpu11_intc 3
				&cpu12_intc 3
				&cpu13_intc 3
				&cpu14_intc 3
				&cpu15_intc 3
				&cpu16_intc 3
				&cpu17_intc 3
				&cpu18_intc 3
				&cpu19_intc 3
				&cpu20_intc 3
				&cpu21_intc 3
				&cpu22_intc 3
				&cpu23_intc 3
				&cpu24_intc 3
				&cpu25_intc 3
				&cpu26_intc 3
				&cpu27_intc 3
				&cpu28_intc 3
				&cpu29_intc 3
				&cpu30_intc 3
				&cpu31_intc 3
				&cpu32_intc 3
				&cpu33_intc 3
				&cpu34_intc 3
				&cpu35_intc 3
				&cpu36_intc 3
				&cpu37_intc 3
				&cpu38_intc 3
				&cpu39_intc 3
				&cpu40_intc 3
				&cpu41_intc 3
				&cpu42_intc 3
				&cpu43_intc 3
				&cpu44_intc 3
				&cpu45_intc 3
				&cpu46_intc 3
				&cpu47_intc 3
				&cpu48_intc 3
				&cpu49_intc 3
				&cpu50_intc 3
				&cpu51_intc 3
				&cpu52_intc 3
				&cpu53_intc 3
				&cpu54_intc 3
				&cpu55_intc 3
				&cpu56_intc 3
				&cpu57_intc 3
				&cpu58_intc 3
				&cpu59_intc 3
				&cpu60_intc 3
				&cpu61_intc 3
				&cpu62_intc 3
				&cpu63_intc 3
				>;
		};

		clint_mtimer: clint-mtimer@6840000000 {
			compatible = "thead,c900-clint-mtimer";
			reg = <0x00000068 0x40000000 0x00000000 0x00008000>;
			interrupts-extended = <
				&cpu0_intc 7
				&cpu1_intc 7
				&cpu2_intc 7
				&cpu3_intc 7
				&cpu4_intc 7
				&cpu5_intc 7
				&cpu6_intc 7
				&cpu7_intc 7
				&cpu8_intc 7
				&cpu9_intc 7
				&cpu10_intc 7
				&cpu11_intc 7
				&cpu12_intc 7
				&cpu13_intc 7
				&cpu14_intc 7
				&cpu15_intc 7
				&cpu16_intc 7
				&cpu17_intc 7
				&cpu18_intc 7
				&cpu19_intc 7
				&cpu20_intc 7
				&cpu21_intc 7
				&cpu22_intc 7
				&cpu23_intc 7
				&cpu24_intc 7
				&cpu25_intc 7
				&cpu26_intc 7
				&cpu27_intc 7
				&cpu28_intc 7
				&cpu29_intc 7
				&cpu30_intc 7
				&cpu31_intc 7
				&cpu32_intc 7
				&cpu33_intc 7
				&cpu34_intc 7
				&cpu35_intc 7
				&cpu36_intc 7
				&cpu37_intc 7
				&cpu38_intc 7
				&cpu39_intc 7
				&cpu40_intc 7
				&cpu41_intc 7
				&cpu42_intc 7
				&cpu43_intc 7
				&cpu44_intc 7
				&cpu45_intc 7
				&cpu46_intc 7
				&cpu47_intc 7
				&cpu48_intc 7
				&cpu49_intc 7
				&cpu50_intc 7
				&cpu51_intc 7
				&cpu52_intc 7
				&cpu53_intc 7
				&cpu54_intc 7
				&cpu55_intc 7
				&cpu56_intc 7
				&cpu57_intc 7
				&cpu58_intc 7
				&cpu59_intc 7
				&cpu60_intc 7
				&cpu61_intc 7
				&cpu62_intc 7
				&cpu63_intc 7
				>;
		};

		intc: interrupt-controller@6d40000000 {
			#interrupt-cells = <1>;
			compatible = "riscv,plic0";
			interrupt-controller;
			interrupts-extended = <
				&cpu0_intc  11 &cpu0_intc  9
				&cpu1_intc  11 &cpu1_intc  9
				&cpu2_intc  11 &cpu2_intc  9
				&cpu3_intc  11 &cpu3_intc  9
				&cpu4_intc  11 &cpu4_intc  9
				&cpu5_intc  11 &cpu5_intc  9
				&cpu6_intc  11 &cpu6_intc  9
				&cpu7_intc  11 &cpu7_intc  9
				&cpu8_intc  11 &cpu8_intc  9
				&cpu9_intc  11 &cpu9_intc  9
				&cpu10_intc  11 &cpu10_intc  9
				&cpu11_intc  11 &cpu11_intc  9
				&cpu12_intc  11 &cpu12_intc  9
				&cpu13_intc  11 &cpu13_intc  9
				&cpu14_intc  11 &cpu14_intc  9
				&cpu15_intc  11 &cpu15_intc  9
				&cpu16_intc  11 &cpu16_intc  9
				&cpu17_intc  11 &cpu17_intc  9
				&cpu18_intc  11 &cpu18_intc  9
				&cpu19_intc  11 &cpu19_intc  9
				&cpu20_intc  11 &cpu20_intc  9
				&cpu21_intc  11 &cpu21_intc  9
				&cpu22_intc  11 &cpu22_intc  9
				&cpu23_intc  11 &cpu23_intc  9
				&cpu24_intc  11 &cpu24_intc  9
				&cpu25_intc  11 &cpu25_intc  9
				&cpu26_intc  11 &cpu26_intc  9
				&cpu27_intc  11 &cpu27_intc  9
				&cpu28_intc  11 &cpu28_intc  9
				&cpu29_intc  11 &cpu29_intc  9
				&cpu30_intc  11 &cpu30_intc  9
				&cpu31_intc  11 &cpu31_intc  9
				&cpu32_intc  11 &cpu32_intc  9
				&cpu33_intc  11 &cpu33_intc  9
				&cpu34_intc  11 &cpu34_intc  9
				&cpu35_intc  11 &cpu35_intc  9
				&cpu36_intc  11 &cpu36_intc  9
				&cpu37_intc  11 &cpu37_intc  9
				&cpu38_intc  11 &cpu38_intc  9
				&cpu39_intc  11 &cpu39_intc  9
				&cpu40_intc  11 &cpu40_intc  9
				&cpu41_intc  11 &cpu41_intc  9
				&cpu42_intc  11 &cpu42_intc  9
				&cpu43_intc  11 &cpu43_intc  9
				&cpu44_intc  11 &cpu44_intc  9
				&cpu45_intc  11 &cpu45_intc  9
				&cpu46_intc  11 &cpu46_intc  9
				&cpu47_intc  11 &cpu47_intc  9
				&cpu48_intc  11 &cpu48_intc  9
				&cpu49_intc  11 &cpu49_intc  9
				&cpu50_intc  11 &cpu50_intc  9
				&cpu51_intc  11 &cpu51_intc  9
				&cpu52_intc  11 &cpu52_intc  9
				&cpu53_intc  11 &cpu53_intc  9
				&cpu54_intc  11 &cpu54_intc  9
				&cpu55_intc  11 &cpu55_intc  9
				&cpu56_intc  11 &cpu56_intc  9
				&cpu57_intc  11 &cpu57_intc  9
				&cpu58_intc  11 &cpu58_intc  9
				&cpu59_intc  11 &cpu59_intc  9
				&cpu60_intc  11 &cpu60_intc  9
				&cpu61_intc  11 &cpu61_intc  9
				&cpu62_intc  11 &cpu62_intc  9
				&cpu63_intc  11 &cpu63_intc  9
				>;
			reg = <0x0000006d 0x40000000 0x00000000 0x10000000>;
			reg-names = "control";
			riscv,max-priority = <7>;
			riscv,ndev = <863>;
		};

		dummy_apb: apb-clock {
			compatible = "fixed-clock";
			clock-frequency = <250000000>;
			clock-output-names = "dummy_apb";
			#clock-cells = <0>;
		};

		dummy_ahb: ahb-clock {
			compatible = "fixed-clock";
			clock-frequency = <250000000>;
			clock-output-names = "dummy_ahb";
			#clock-cells = <0>;
		};

		dummy_axi: axi-clock {
			compatible = "fixed-clock";
			clock-frequency = <25000000>;
			clock-output-names = "dummy_axi";
			#clock-cells = <0>;
		};

		uart0: serial@7030001000 {
			compatible = "snps,dw-apb-uart";
			reg = <0x00000070 0x30001000 0x00000000 0x00001000>;
			interrupt-parent = <&intc>;
			interrupts = <42>;
			clock-frequency = <153600>;
			clock-names = "baudclk";
			reg-shift = <2>;
			reg-io-width = <4>;
		};
	};

	aliases {
		serial0 = &uart0;
	};

	chosen {
		bootargs = "console=ttyS0,9600 earlycon rdinit=/init root=/dev/ram0 rw initrd=0x8b000000,32M rdmem=0x100000000,4096M";
		stdout-path = "serial0";
	};
};
